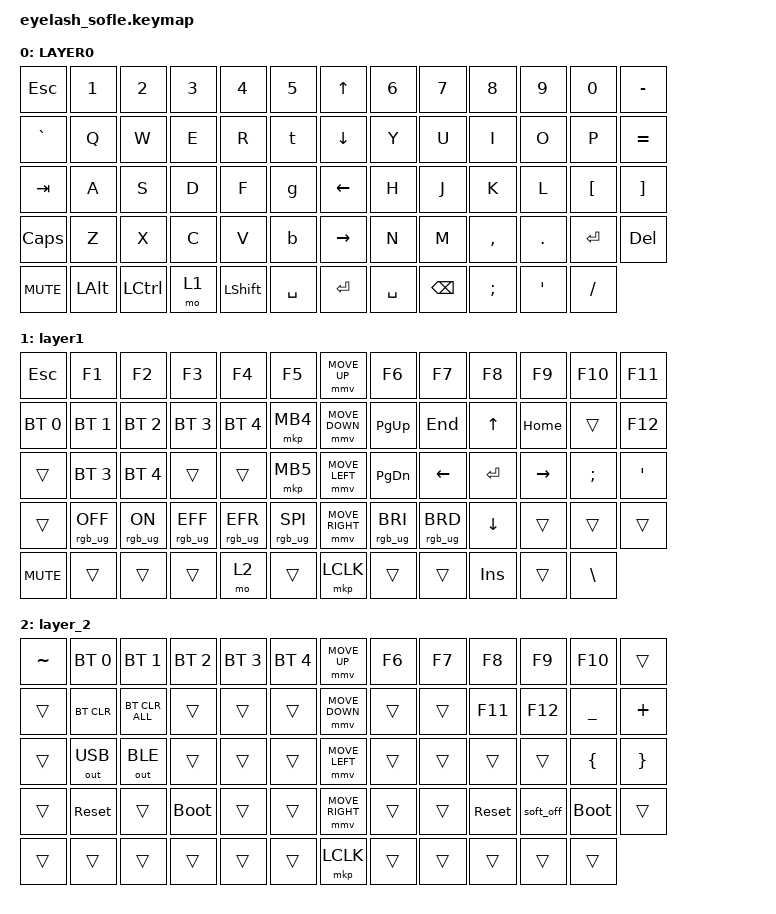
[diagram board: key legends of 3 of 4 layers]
#define ZMK_POINTING_DEFAULT_MOVE_VAL 1200  // 600
#define ZMK_POINTING_DEFAULT_SCRL_VAL 35    // 10

#include <input/processors.dtsi>
#include <zephyr/dt-bindings/input/input-event-codes.h>
#include <behaviors.dtsi>
#include <dt-bindings/zmk/bt.h>
#include <dt-bindings/zmk/keys.h>
#include <dt-bindings/zmk/outputs.h>
#include <dt-bindings/zmk/pointing.h>
#include <dt-bindings/zmk/rgb.h>

/ {
    zip_scroll_scaler: zip_scroll_scaler {
        compatible = "zmk,input-processor-scaler";
        #input-processor-cells = <2>;
        type = <INPUT_EV_REL>;
        codes = <INPUT_REL_WHEEL INPUT_REL_HWHEEL>;
        track-remainders;
    };
};

&mmv_input_listener { input-processors = <&zip_xy_scaler 2 1>; };

&msc_input_listener { input-processors = <&zip_scroll_scaler 2 1>; };

&msc {
    acceleration-exponent = <0>;      // 0
    time-to-max-speed-ms = <0>;       // 300
    delay-ms = <0>;                    // 0
};

&mmv {
    time-to-max-speed-ms = <400>;
    acceleration-exponent = <1>;
};

/ {
    scroll_encoder: scroll_encoder {
        compatible = "zmk,behavior-sensor-rotate";
        #sensor-binding-cells = <0>;
        bindings = <&msc SCRL_DOWN>, <&msc SCRL_UP>;

        tap-ms = <100>;
    };

    macros {
        shift_MB3: shift_MB3 {
            compatible = "zmk,behavior-macro";
            #binding-cells = <0>;
            bindings =
                <&macro_press &kp LEFT_SHIFT>,
                <&macro_press &mkp MB3>,
                <&macro_pause_for_release>,
                <&macro_release &mkp MB3>,
                <&macro_release &kp LEFT_SHIFT>;

            label = "SHIFT_MB3";
        };
    };

    behaviors {
    };

    keymap {
        compatible = "zmk,keymap";

        layer0 {
            bindings = <
&kp ESC     &kp N1     &kp N2       &kp N3       &kp N4  &kp N5        &kp UP_ARROW     &kp N6     &kp N7     &kp N8     &kp N9            &kp N0       &kp MINUS
&kp GRAVE     &kp Q      &kp W        &kp E        &kp R   &t          &kp DOWN_ARROW   &kp Y      &kp U      &kp I      &kp O             &kp P        &kp EQUAL
&kp TAB    &kp A      &kp S        &kp D        &kp F   &g          &kp LEFT_ARROW   &kp H      &kp J      &kp K      &kp L             &kp LEFT_BRACKET    &kp RIGHT_BRACKET
&kp CAPS   &kp Z      &kp X        &kp C        &kp V   &b          &kp RIGHT_ARROW  &kp N      &kp M      &kp COMMA  &kp DOT           &kp ENTER    &kp DELETE
&kp C_MUTE  &kp LEFT_ALT  &kp LCTRL   &mo 1  &kp LEFT_SHIFT  &kp SPACE    &kp ENTER        &kp SPACE  &kp BACKSPACE  &kp SEMI     &kp SQT  &kp FSLH
            >;
            sensor-bindings = <&scroll_encoder>;
            
            display-name = "LAYER0";
        };

        layer_1 {
            bindings = <
&kp ESC   &kp F1             &kp F2          &kp F3             &kp F4             &kp F5               &mmv MOVE_UP         &kp F6             &kp F7           &kp F8      &kp F9     &kp F10       &kp F11
&bt BT_SEL 0  &bt BT_SEL 1    &bt BT_SEL 2    &bt BT_SEL 3  &bt BT_SEL 4    &mkp MB4             &mmv MOVE_DOWN       &kp PG_UP          &kp END          &kp UP      &kp HOME    &trans       &kp F12
&trans      &bt BT_SEL 3  &bt BT_SEL 4    &trans             &trans             &mkp MB5             &mmv MOVE_LEFT       &kp PG_DN          &kp LEFT         &kp ENTER   &kp RIGHT  &kp SEMI     &kp APOS
&trans      &rgb_ug RGB_OFF  &rgb_ug RGB_ON  &rgb_ug RGB_EFF  &rgb_ug RGB_EFR  &rgb_ug RGB_SPI      &mmv MOVE_RIGHT      &rgb_ug RGB_BRI    &rgb_ug RGB_BRD  &kp DOWN      &trans    &trans     &trans
&kp C_MUTE  &trans            &trans          &trans             &mo 2              &trans               &mkp LCLK            &trans             &trans           &kp INSERT      &trans    &kp BSLH
            >;

            display-name = "layer1";
            sensor-bindings = <&inc_dec_kp C_VOLUME_UP C_VOL_DN>;
            
        };

        layer_2 {
            bindings = <
&kp TILDE  &bt BT_SEL 0  &bt BT_SEL 1    &bt BT_SEL 2  &bt BT_SEL 3  &bt BT_SEL 4    &mmv MOVE_UP     &kp F6  &kp F7  &kp F8      &kp F9      &kp F10      &trans
&trans     &bt BT_CLR    &bt BT_CLR_ALL  &trans        &trans        &trans          &mmv MOVE_DOWN   &trans  &trans  &kp F11     &kp F12     &kp UNDER    &kp PLUS
&trans     &out OUT_USB  &out OUT_BLE    &trans        &trans        &trans          &mmv MOVE_LEFT   &trans  &trans  &trans      &trans      &kp LBRC     &kp RBRC
&trans     &sys_reset    &trans          &bootloader   &trans        &trans          &mmv MOVE_RIGHT  &trans  &trans  &sys_reset  &soft_off   &bootloader  &trans
&trans     &trans        &trans          &trans        &trans        &trans          &mkp LCLK        &trans  &trans  &trans      &trans      &trans
            >;

            sensor-bindings = <&scroll_encoder>;
        };

        layer_3 {
            bindings = <
&trans  &trans  &trans  &trans  &trans  &trans    &trans  &trans  &trans  &trans  &trans  &trans  &trans
&trans  &trans  &trans  &trans  &trans  &trans    &trans  &trans  &trans  &trans  &trans  &trans  &trans
&trans  &trans  &trans  &trans  &trans  &trans    &trans  &trans  &trans  &trans  &trans  &trans  &trans
&trans  &trans  &trans  &trans  &trans  &trans    &trans  &trans  &trans  &trans  &trans  &trans  &trans
&trans  &trans  &trans  &trans  &trans  &trans    &trans  &trans  &trans  &trans  &trans  &trans  &trans
            >;
        };
    };
};
